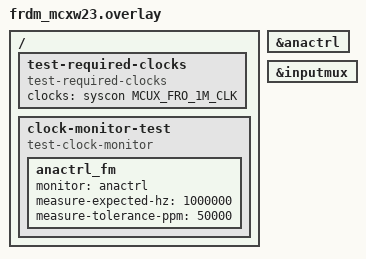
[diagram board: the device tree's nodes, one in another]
/*
 * SPDX-FileCopyrightText: 2026 NXP
 *
 * SPDX-License-Identifier: Apache-2.0
 */

#include <zephyr/dt-bindings/clock/mcux_lpc_syscon_clock.h>

/ {
	test-required-clocks {
		compatible = "test-required-clocks";
		clocks = <&syscon MCUX_FRO_1M_CLK>;
	};

	clock-monitor-test {
		compatible = "test-clock-monitor";

		/* MEASURE only; reference = system AHB clock (~32 MHz), target = 1 MHz
		 * FRO.
		 */
		anactrl_fm {
			monitor = <&anactrl>;
			measure-expected-hz = <1000000>;
			measure-tolerance-ppm = <50000>;
		};
	};
};

&anactrl {
	status = "okay";
};

&inputmux {
	status = "okay";
};
